AUTOSAR XML (schema 4-2-2)
package /ASWC_ASW_COM_STD
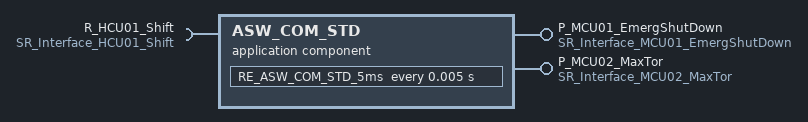
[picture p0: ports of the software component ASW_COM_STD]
  application sw component type ASW_COM_STD
    provide port P_MCU01_EmergShutDown: provided-interface=SR_Interface_MCU01_EmergShutDown
    provide port P_MCU02_MaxTor: provided-interface=SR_Interface_MCU02_MaxTor
    require port R_HCU01_Shift: nonqueued-receiver-com-spec{data-element=DE_HCU01_Shift, alive-timeout=0.3, init-value=0}, required-interface=SR_Interface_HCU01_Shift
    behavior IB_ASW_COM_STD
      timing event TE_5ms_RE_ASW_COM_STD: start-on-event=RE_ASW_COM_STD_5ms, period=0.005
      runnable RE_ASW_COM_STD_5ms
        data-receive-point-by-arguments:
          access REC_HCU01_Shift: accessed-variable=R_HCU01_Shift.DE_HCU01_Shift
        data-send-points:
          access SEND_MCU01_EmergShutDown: accessed-variable=P_MCU01_EmergShutDown.DE_MCU01_EmergShutDown
          access SEND_MCU02_MaxTor: accessed-variable=P_MCU02_MaxTor.DE_MCU02_MaxTor
